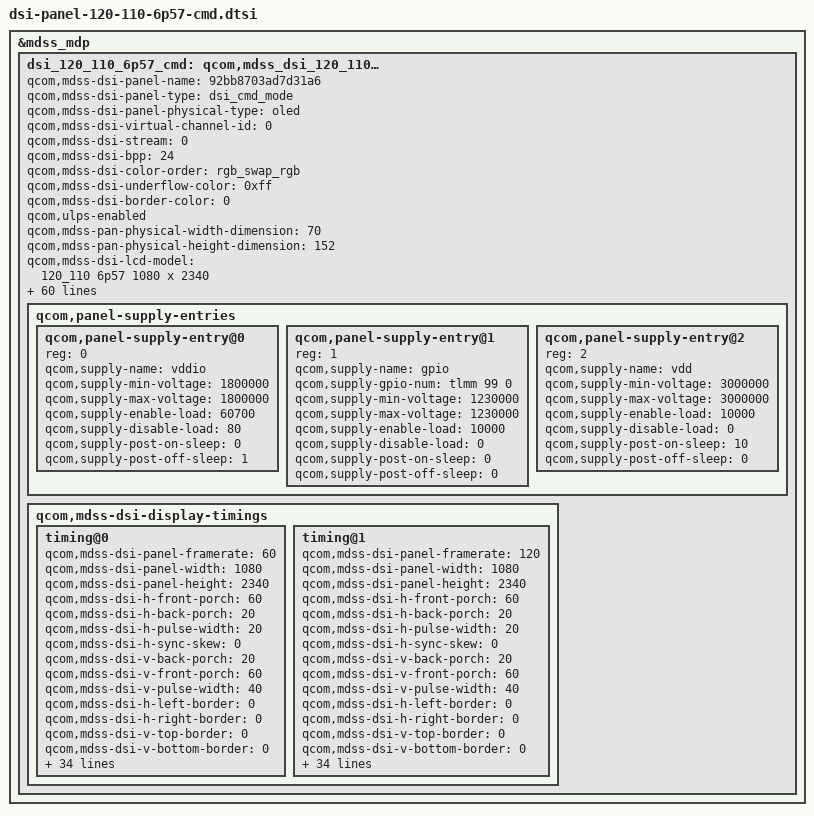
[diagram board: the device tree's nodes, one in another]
&mdss_mdp {
	dsi_120_110_6p57_cmd: qcom,mdss_dsi_120_110_6p57_cmd {
		qcom,mdss-dsi-panel-name = "92bb8703ad7d31a6";
		qcom,mdss-dsi-panel-type = "dsi_cmd_mode";
		qcom,mdss-dsi-panel-physical-type = "oled";
		qcom,mdss-dsi-virtual-channel-id = <0>;
		qcom,mdss-dsi-stream = <0>;
		qcom,mdss-dsi-bpp = <24>;
		qcom,mdss-dsi-color-order = "rgb_swap_rgb";
		qcom,mdss-dsi-underflow-color = <0xff>;
		qcom,mdss-dsi-border-color = <0>;
		qcom,ulps-enabled;
		qcom,mdss-pan-physical-width-dimension = <70>;
		qcom,mdss-pan-physical-height-dimension = <152>;
		qcom,mdss-dsi-lcd-model = "120_110 6p57 1080 x 2340";

		/* mipi dsi setting */
		qcom,dsi-ctrl-num = <0>;
		qcom,dsi-phy-num = <0>;
		qcom,dsi-sec-ctrl-num = <1>;
		qcom,dsi-sec-phy-num = <1>;
		qcom,mdss-dsi-traffic-mode = "non_burst_sync_event";
		qcom,mdss-dsi-lane-map = "lane_map_0123";
		qcom,mdss-dsi-bllp-eof-power-mode;
		qcom,mdss-dsi-bllp-power-mode;
		qcom,mdss-dsi-lane-0-state;
		qcom,mdss-dsi-lane-1-state;
		qcom,mdss-dsi-lane-2-state;
		qcom,mdss-dsi-lane-3-state;
		qcom,mdss-dsi-dma-trigger = "trigger_sw";
		qcom,mdss-dsi-mdp-trigger = "none";
		qcom,dsi-select-clocks = "mux_byte_clk0", "mux_pixel_clk0";
		qcom,dsi-select-sec-clocks = "mux_byte_clk1", "mux_pixel_clk1";

		/* TE setting */
		qcom,mdss-dsi-te-pin-select = <1>;
		qcom,mdss-dsi-wr-mem-start = <0x2c>;
		qcom,mdss-dsi-wr-mem-continue = <0x3c>;
		qcom,mdss-dsi-te-dcs-command = <1>;
		qcom,mdss-dsi-te-check-enable;
		qcom,mdss-dsi-te-using-te-pin;

		/* hdr setting */
		qcom,mdss-dsi-panel-hdr-enabled;
		qcom,mdss-dsi-panel-hdr-color-primaries = <14500 15500 32000
			17000 15500 30000 8000 3000>;
		qcom,mdss-dsi-panel-peak-brightness = <4200000>;
		qcom,mdss-dsi-panel-blackness-level = <3230>;

		/* hbm enable */
		qcom,mdss-dsi-panel-hbm-enabled;

		/* gpio setting */
		qcom,dsi-panel-gpio-address = <0x0F100000 0x1000>;
		qcom,dsi-panel-gpio-pins = <44 99>;
		qcom,dsi-panel-gpio-names = "reset-gpio", "vdd-gpio";

		/* esd check setting */
		qcom,mdss-dsi-panel-status-check-mode = "reg_read";
		qcom,mdss-dsi-panel-status-command = [06 01 00 01 00 00 01 0a];
		qcom,mdss-dsi-panel-status-command-state = "dsi_lp_mode";
		qcom,mdss-dsi-panel-status-value = <0x9c>;
		qcom,mdss-dsi-panel-status-read-length = <1>;
		qcom,esd-check-enabled;

		/* check reg */
		qcom,mdss-dsi-panel-lcd-check-reg-enabled;
		qcom,mdss-dsi-panel-lcd-check-reg-expect_vals = <0x9c>;

		/* oem info */
		qcom,mdss-dsi-panel-oem-info-enabled;
		qcom,mdss-dsi-panel-oem-2d-barcode-enabled;
		qcom,mdss-dsi-panel-oem-sn-enabled;

		/* backlight setting */
		qcom,mdss-dsi-bl-pmic-control-type = "bl_ctrl_dcs";
		qcom,mdss-dsi-bl-min-level = <9>;
		qcom,mdss-dsi-bl-max-level = <4095>;
		qcom,mdss-brightness-max-level = <4095>;
		qcom,mdss-dsi-bl-inverted-dbv;
		qcom,mdss-dsi-bl-max-nit = <1000>;

		/* dfps setting */
		qcom,dsi-fps-list = <60 120>;

		/* power on/off timing setting */
		qcom,platform-reset-gpio = <&tlmm 44 0>;
		qcom,mdss-dsi-reset-sequence = <1 1>, <0 1>, <1 10>;
		qcom,panel-supply-entries {
			qcom,panel-supply-entry@0 {
					reg = <0>;
					qcom,supply-name = "vddio";
					qcom,supply-min-voltage = <1800000>;
					qcom,supply-max-voltage = <1800000>;
					qcom,supply-enable-load = <60700>;
					qcom,supply-disable-load = <80>;
					qcom,supply-post-on-sleep = <0>;
					qcom,supply-post-off-sleep = <1>;
			};
			qcom,panel-supply-entry@1 {
					reg = <1>;
					qcom,supply-name = "gpio";
					qcom,supply-gpio-num = <&tlmm 99 0>;
					qcom,supply-min-voltage = <1230000>;
					qcom,supply-max-voltage = <1230000>;
					qcom,supply-enable-load = <10000>;
					qcom,supply-disable-load = <0>;
					qcom,supply-post-on-sleep = <0>;
					qcom,supply-post-off-sleep = <0>;
			};
			qcom,panel-supply-entry@2 {
					reg = <2>;
					qcom,supply-name = "vdd";
					qcom,supply-min-voltage = <3000000>;
					qcom,supply-max-voltage = <3000000>;
					qcom,supply-enable-load = <10000>;
					qcom,supply-disable-load = <0>;
					qcom,supply-post-on-sleep = <10>;
					qcom,supply-post-off-sleep = <0>;
			};
		};
		/* display timing0 */
		qcom,mdss-dsi-display-timings {
			timing@0 {
				qcom,mdss-dsi-panel-framerate = <60>;
				qcom,mdss-dsi-panel-width = <1080>;
				qcom,mdss-dsi-panel-height = <2340>;
				qcom,mdss-dsi-h-front-porch = <60>;
				qcom,mdss-dsi-h-back-porch = <20>;
				qcom,mdss-dsi-h-pulse-width = <20>;
				qcom,mdss-dsi-h-sync-skew = <0>;
				qcom,mdss-dsi-v-back-porch = <20>;
				qcom,mdss-dsi-v-front-porch = <60>;
				qcom,mdss-dsi-v-pulse-width = <40>;
				qcom,mdss-dsi-h-left-border = <0>;
				qcom,mdss-dsi-h-right-border = <0>;
				qcom,mdss-dsi-v-top-border = <0>;
				qcom,mdss-dsi-v-bottom-border = <0>;
				qcom,mdss-dsi-panel-jitter = <0x4 0x1>;

				qcom,mdss-dsi-on-command = [
					15 01 00 00 00 00 02 fe d2
					15 01 00 00 00 00 02 4f 08
					15 01 00 00 00 00 02 fe d2
					15 01 00 00 00 00 02 50 11
					15 01 00 00 00 00 02 51 89
					15 01 00 00 00 00 02 52 30
					15 01 00 00 00 00 02 53 09
					15 01 00 00 00 00 02 54 24
					15 01 00 00 00 00 02 55 04
					15 01 00 00 00 00 02 56 38
					15 01 00 00 00 00 02 58 00
					15 01 00 00 00 00 02 59 14
					15 01 00 00 00 00 02 5a 04
					15 01 00 00 00 00 02 5b 38
					15 01 00 00 00 00 02 5c 02
					15 01 00 00 00 00 02 5d 00
					15 01 00 00 00 00 02 5e 20
					15 01 00 00 00 00 02 5f 02
					15 01 00 00 00 00 02 60 8c
					15 01 00 00 00 00 02 61 00
					15 01 00 00 00 00 02 62 0f
					15 01 00 00 00 00 02 63 0c
					15 01 00 00 00 00 02 64 05
					15 01 00 00 00 00 02 65 0e
					15 01 00 00 00 00 02 66 02
					15 01 00 00 00 00 02 67 8b
					15 01 00 00 00 00 02 68 18
					15 01 00 00 00 00 02 69 00
					15 01 00 00 00 00 02 6a 10
					15 01 00 00 00 00 02 6b f0
					15 01 00 00 00 00 02 6c 03
					15 01 00 00 00 00 02 6d 0c
					15 01 00 00 00 00 02 6e 20
					15 01 00 00 00 00 02 6f 00
					15 01 00 00 00 00 02 70 06
					15 01 00 00 00 00 02 71 0b
					15 01 00 00 00 00 02 72 0b
					15 01 00 00 00 00 02 73 33
					15 01 00 00 00 00 02 74 0e
					15 01 00 00 00 00 02 75 1c
					15 01 00 00 00 00 02 76 2a
					15 01 00 00 00 00 02 77 38
					15 01 00 00 00 00 02 78 46
					15 01 00 00 00 00 02 79 54
					15 01 00 00 00 00 02 7a 62
					15 01 00 00 00 00 02 7b 69
					15 01 00 00 00 00 02 7c 70
					15 01 00 00 00 00 02 7d 77
					15 01 00 00 00 00 02 7e 79
					15 01 00 00 00 00 02 7f 7b
					15 01 00 00 00 00 02 80 7d
					15 01 00 00 00 00 02 81 7e
					15 01 00 00 00 00 02 82 01
					15 01 00 00 00 00 02 83 02
					15 01 00 00 00 00 02 84 01
					15 01 00 00 00 00 02 85 00
					15 01 00 00 00 00 02 86 09
					15 01 00 00 00 00 02 87 40
					15 01 00 00 00 00 02 88 09
					15 01 00 00 00 00 02 89 be
					15 01 00 00 00 00 02 8a 19
					15 01 00 00 00 00 02 8b fc
					15 01 00 00 00 00 02 8c 19
					15 01 00 00 00 00 02 8d fa
					15 01 00 00 00 00 02 8e 19
					15 01 00 00 00 00 02 8f f8
					15 01 00 00 00 00 02 90 1a
					15 01 00 00 00 00 02 91 38
					15 01 00 00 00 00 02 92 1a
					15 01 00 00 00 00 02 93 78
					15 01 00 00 00 00 02 94 1a
					15 01 00 00 00 00 02 95 b6
					15 01 00 00 00 00 02 96 2a
					15 01 00 00 00 00 02 97 f6
					15 01 00 00 00 00 02 98 2b
					15 01 00 00 00 00 02 99 34
					15 01 00 00 00 00 02 9a 2b
					15 01 00 00 00 00 02 9b 74
					15 01 00 00 00 00 02 9c 3b
					15 01 00 00 00 00 02 9d 74
					15 01 00 00 00 00 02 9e 6b
					15 01 00 00 00 00 02 9f f4
					15 01 00 00 00 00 02 a2 04
					15 01 00 00 00 00 02 a3 38
					15 01 00 00 00 00 02 a4 00
					15 01 00 00 00 00 02 a5 00
					15 01 00 00 00 00 02 a6 00
					15 01 00 00 00 00 02 a7 00
					15 01 00 00 00 00 02 a9 00
					15 01 00 00 00 00 02 aa 00
					15 01 00 00 00 00 02 a0 80
					15 01 00 00 00 00 02 fe 98
					15 01 00 00 00 00 02 14 03
					15 01 00 00 00 00 02 fe 38
					15 01 00 00 00 00 02 17 0f
					15 01 00 00 00 00 02 18 0f
					15 01 00 00 00 00 02 fe 40
					15 01 00 00 00 00 02 bd 00
					15 01 00 00 00 00 02 fe 00
					15 01 00 00 00 00 02 fa 01
					15 01 00 00 00 00 02 fe 00
					15 01 00 00 00 00 02 c2 08
					15 01 00 00 00 00 02 35 00
					39 01 00 00 00 00 03 51 0d bb
					05 01 00 00 46 00 01 11
					05 01 00 00 4f 00 01 29
				];

				qcom,mdss-dsi-off-command = [
					05 01 00 00 00 00 01 28
					05 01 00 00 78 00 01 10
				];

				qcom,mdss-dsi-fp-hbm-enable-commands = [
					39 01 00 00 00 00 03 51 0F FF
				];

				qcom,mdss-dsi-timing-switch-command = [
					15 01 00 00 00 00 02 FE 40
					15 01 00 00 09 00 02 BD 00
					15 01 00 00 00 00 02 FE 00
				];

//				qcom,mdss-dsi-lp1-command = [
//					15 01 00 00 00 00 02 FE 00
//					05 01 00 00 00 00 01 39
//				];

//				qcom,mdss-dsi-nolp-command = [
//					15 01 00 00 00 00 02 FE 00
//					05 01 00 00 00 00 01 38
//				];

				qcom,mdss-dsi-panel-lcd-check-reg-commands = [
					06 01 00 01 00 00 01 0a
				];

				qcom,mdss-dsi-oeminfo-read-commands = [
					15 01 00 00 00 00 02 FE C2
					06 01 00 01 00 00 01 00
					06 01 00 01 00 00 01 01
					06 01 00 01 00 00 01 02
					06 01 00 01 00 00 01 03
					06 01 00 01 00 00 01 04
					06 01 00 01 00 00 01 05
					06 01 00 01 00 00 01 06
					06 01 00 01 00 00 01 07
					06 01 00 01 00 00 01 08
					06 01 00 01 00 00 01 09
					06 01 00 01 00 00 01 0A
					06 01 00 01 00 00 01 0B
					06 01 00 01 00 00 01 0C
					06 01 00 01 00 00 01 0D
					06 01 00 01 00 00 01 0E
					06 01 00 01 00 00 01 0F
					06 01 00 01 00 00 01 10
					06 01 00 01 00 00 01 11
					06 01 00 01 00 00 01 12
					06 01 00 01 00 00 01 13
					06 01 00 01 00 00 01 14
				];

				qcom,mdss-dsi-on-command-state = "dsi_lp_mode";
				qcom,mdss-dsi-off-command-state = "dsi_hs_mode";
				qcom,mdss-dsi-lp1-command-state = "dsi_hs_mode";
				qcom,mdss-dsi-nolp-command-state = "dsi_hs_mode";
				qcom,mdss-dsi-panel-lcd-check-reg-commands-state =
					"dsi_lp_mode";
				qcom,mdss-dsi-oeminfo-read-commands-state =
					"dsi_lp_mode";

				qcom,mdss-dsi-h-sync-pulse = <0>;
				qcom,compression-mode = "dsc";
				qcom,mdss-dsc-version = <0x12>;
				qcom,mdss-dsc-slice-height = <20>;
				qcom,mdss-dsc-slice-width = <1080>;
				qcom,mdss-dsc-slice-per-pkt = <1>;
				qcom,mdss-dsc-bit-per-component = <10>;
				qcom,mdss-dsc-bit-per-pixel = <8>;
				qcom,mdss-dsc-block-prediction-enable;
				qcom,mdss-dsi-panel-phy-timings = [00 11 03 04 12 1e 04
					04 04 03 02 04 0e 09];
				qcom,display-topology = <1 1 1>;
				qcom,default-topology-index = <0>;
			};
			timing@1 {
				qcom,mdss-dsi-panel-framerate = <120>;
				qcom,mdss-dsi-panel-width = <1080>;
				qcom,mdss-dsi-panel-height = <2340>;
				qcom,mdss-dsi-h-front-porch = <60>;
				qcom,mdss-dsi-h-back-porch = <20>;
				qcom,mdss-dsi-h-pulse-width = <20>;
				qcom,mdss-dsi-h-sync-skew = <0>;
				qcom,mdss-dsi-v-back-porch = <20>;
				qcom,mdss-dsi-v-front-porch = <60>;
				qcom,mdss-dsi-v-pulse-width = <40>;
				qcom,mdss-dsi-h-left-border = <0>;
				qcom,mdss-dsi-h-right-border = <0>;
				qcom,mdss-dsi-v-top-border = <0>;
				qcom,mdss-dsi-v-bottom-border = <0>;
				qcom,mdss-dsi-panel-jitter = <0x4 0x1>;

				qcom,mdss-dsi-on-command = [
					15 01 00 00 00 00 02 fe d2
					15 01 00 00 00 00 02 4f 08
					15 01 00 00 00 00 02 fe d2
					15 01 00 00 00 00 02 50 11
					15 01 00 00 00 00 02 51 89
					15 01 00 00 00 00 02 52 30
					15 01 00 00 00 00 02 53 09
					15 01 00 00 00 00 02 54 24
					15 01 00 00 00 00 02 55 04
					15 01 00 00 00 00 02 56 38
					15 01 00 00 00 00 02 58 00
					15 01 00 00 00 00 02 59 14
					15 01 00 00 00 00 02 5a 04
					15 01 00 00 00 00 02 5b 38
					15 01 00 00 00 00 02 5c 02
					15 01 00 00 00 00 02 5d 00
					15 01 00 00 00 00 02 5e 20
					15 01 00 00 00 00 02 5f 02
					15 01 00 00 00 00 02 60 8c
					15 01 00 00 00 00 02 61 00
					15 01 00 00 00 00 02 62 0f
					15 01 00 00 00 00 02 63 0c
					15 01 00 00 00 00 02 64 05
					15 01 00 00 00 00 02 65 0e
					15 01 00 00 00 00 02 66 02
					15 01 00 00 00 00 02 67 8b
					15 01 00 00 00 00 02 68 18
					15 01 00 00 00 00 02 69 00
					15 01 00 00 00 00 02 6a 10
					15 01 00 00 00 00 02 6b f0
					15 01 00 00 00 00 02 6c 03
					15 01 00 00 00 00 02 6d 0c
					15 01 00 00 00 00 02 6e 20
					15 01 00 00 00 00 02 6f 00
					15 01 00 00 00 00 02 70 06
					15 01 00 00 00 00 02 71 0b
					15 01 00 00 00 00 02 72 0b
					15 01 00 00 00 00 02 73 33
					15 01 00 00 00 00 02 74 0e
					15 01 00 00 00 00 02 75 1c
					15 01 00 00 00 00 02 76 2a
					15 01 00 00 00 00 02 77 38
					15 01 00 00 00 00 02 78 46
					15 01 00 00 00 00 02 79 54
					15 01 00 00 00 00 02 7a 62
					15 01 00 00 00 00 02 7b 69
					15 01 00 00 00 00 02 7c 70
					15 01 00 00 00 00 02 7d 77
					15 01 00 00 00 00 02 7e 79
					15 01 00 00 00 00 02 7f 7b
					15 01 00 00 00 00 02 80 7d
					15 01 00 00 00 00 02 81 7e
					15 01 00 00 00 00 02 82 01
					15 01 00 00 00 00 02 83 02
					15 01 00 00 00 00 02 84 01
					15 01 00 00 00 00 02 85 00
					15 01 00 00 00 00 02 86 09
					15 01 00 00 00 00 02 87 40
					15 01 00 00 00 00 02 88 09
					15 01 00 00 00 00 02 89 be
					15 01 00 00 00 00 02 8a 19
					15 01 00 00 00 00 02 8b fc
					15 01 00 00 00 00 02 8c 19
					15 01 00 00 00 00 02 8d fa
					15 01 00 00 00 00 02 8e 19
					15 01 00 00 00 00 02 8f f8
					15 01 00 00 00 00 02 90 1a
					15 01 00 00 00 00 02 91 38
					15 01 00 00 00 00 02 92 1a
					15 01 00 00 00 00 02 93 78
					15 01 00 00 00 00 02 94 1a
					15 01 00 00 00 00 02 95 b6
					15 01 00 00 00 00 02 96 2a
					15 01 00 00 00 00 02 97 f6
					15 01 00 00 00 00 02 98 2b
					15 01 00 00 00 00 02 99 34
					15 01 00 00 00 00 02 9a 2b
					15 01 00 00 00 00 02 9b 74
					15 01 00 00 00 00 02 9c 3b
					15 01 00 00 00 00 02 9d 74
					15 01 00 00 00 00 02 9e 6b
					15 01 00 00 00 00 02 9f f4
					15 01 00 00 00 00 02 a2 04
					15 01 00 00 00 00 02 a3 38
					15 01 00 00 00 00 02 a4 00
					15 01 00 00 00 00 02 a5 00
					15 01 00 00 00 00 02 a6 00
					15 01 00 00 00 00 02 a7 00
					15 01 00 00 00 00 02 a9 00
					15 01 00 00 00 00 02 aa 00
					15 01 00 00 00 00 02 a0 80
					15 01 00 00 00 00 02 fe 98
					15 01 00 00 00 00 02 14 03
					15 01 00 00 00 00 02 fe 38
					15 01 00 00 00 00 02 17 0f
					15 01 00 00 00 00 02 18 0f
					15 01 00 00 00 00 02 fe 40
					15 01 00 00 00 00 02 bd 05
					15 01 00 00 00 00 02 fe 00
					15 01 00 00 00 00 02 fa 01
					15 01 00 00 00 00 02 fe 00
					15 01 00 00 00 00 02 c2 08
					15 01 00 00 00 00 02 35 00
					39 01 00 00 00 00 03 51 0d bb
					05 01 00 00 46 00 01 11
					05 01 00 00 4f 00 01 29
				];

				qcom,mdss-dsi-off-command = [
					05 01 00 00 00 00 01 28
					05 01 00 00 78 00 01 10
				];

				qcom,mdss-dsi-fp-hbm-enable-commands = [
					39 01 00 00 00 00 03 51 0F FF
				];

				qcom,mdss-dsi-timing-switch-command = [
					15 01 00 00 00 00 02 FE 40
					15 01 00 00 00 00 02 BD 05
					15 01 00 00 00 00 02 FE 00
				];

//				qcom,mdss-dsi-lp1-command = [
//					15 01 00 00 00 00 02 FE 00
//					05 01 00 00 00 00 01 39
//				];

//				qcom,mdss-dsi-nolp-command = [
//					15 01 00 00 00 00 02 FE 00
//					05 01 00 00 00 00 01 38
//				];

				qcom,mdss-dsi-panel-lcd-check-reg-commands = [
					06 01 00 01 00 00 01 0a
				];

				qcom,mdss-dsi-oeminfo-read-commands = [
					15 01 00 00 00 00 02 FE C2
					06 01 00 01 00 00 01 00
					06 01 00 01 00 00 01 01
					06 01 00 01 00 00 01 02
					06 01 00 01 00 00 01 03
					06 01 00 01 00 00 01 04
					06 01 00 01 00 00 01 05
					06 01 00 01 00 00 01 06
					06 01 00 01 00 00 01 07
					06 01 00 01 00 00 01 08
					06 01 00 01 00 00 01 09
					06 01 00 01 00 00 01 0A
					06 01 00 01 00 00 01 0B
					06 01 00 01 00 00 01 0C
					06 01 00 01 00 00 01 0D
					06 01 00 01 00 00 01 0E
					06 01 00 01 00 00 01 0F
					06 01 00 01 00 00 01 10
					06 01 00 01 00 00 01 11
					06 01 00 01 00 00 01 12
					06 01 00 01 00 00 01 13
					06 01 00 01 00 00 01 14
				];

				qcom,mdss-dsi-on-command-state = "dsi_lp_mode";
				qcom,mdss-dsi-off-command-state = "dsi_hs_mode";
				qcom,mdss-dsi-lp1-command-state = "dsi_hs_mode";
				qcom,mdss-dsi-nolp-command-state = "dsi_hs_mode";
				qcom,mdss-dsi-panel-lcd-check-reg-commands-state =
					"dsi_lp_mode";
				qcom,mdss-dsi-oeminfo-read-commands-state =
					"dsi_lp_mode";

				qcom,mdss-dsi-h-sync-pulse = <0>;
				qcom,compression-mode = "dsc";
				qcom,mdss-dsc-version = <0x12>;
				qcom,mdss-dsc-slice-height = <20>;
				qcom,mdss-dsc-slice-width = <1080>;
				qcom,mdss-dsc-slice-per-pkt = <1>;
				qcom,mdss-dsc-bit-per-component = <10>;
				qcom,mdss-dsc-bit-per-pixel = <8>;
				qcom,mdss-dsc-block-prediction-enable;
				qcom,mdss-dsi-panel-phy-timings = [00 1c 07 07 17 16 07
					07 07 08 02 04 18 0c];
				qcom,display-topology = <1 1 1>;
				qcom,default-topology-index = <0>;
			};
		};
	};
};
